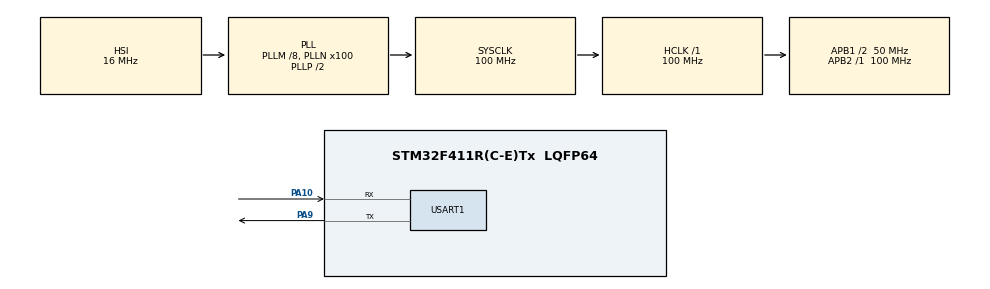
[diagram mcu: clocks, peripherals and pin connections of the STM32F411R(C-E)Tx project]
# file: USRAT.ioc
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Dma.Request0=USART1_RX
Dma.USART1_RX.0.Direction=DMA_PERIPH_TO_MEMORY
Dma.USART1_RX.0.FIFOMode=DMA_FIFOMODE_DISABLE
Dma.USART1_RX.0.Instance=DMA2_Stream2
Dma.USART1_RX.0.MemDataAlignment=DMA_MDATAALIGN_BYTE
Dma.USART1_RX.0.MemInc=DMA_MINC_ENABLE
Dma.USART1_RX.0.Mode=DMA_NORMAL
Dma.USART1_RX.0.PeriphDataAlignment=DMA_PDATAALIGN_BYTE
Dma.USART1_RX.0.PeriphInc=DMA_PINC_DISABLE
Dma.USART1_RX.0.Priority=DMA_PRIORITY_LOW
Mcu.Family=STM32F4
Mcu.Name=STM32F411R(C-E)Tx
Mcu.Package=LQFP64
NVIC.DMA2_Stream2_IRQn=true\:0\:0\:false\:false\:true\:false\:true\:true
NVIC.PriorityGroup=NVIC_PRIORITYGROUP_4
NVIC.USART1_IRQn=true\:0\:0\:false\:false\:true\:true\:true\:true
PA10.Mode=Asynchronous
PA10.Signal=USART1_RX
PA13.Mode=Serial_Wire
PA13.Signal=SYS_JTMS-SWDIO
PA14.Mode=Serial_Wire
PA14.Signal=SYS_JTCK-SWCLK
PA9.Mode=Asynchronous
PA9.Signal=USART1_TX
PC14-OSC32_IN.Mode=LSE-External-Oscillator
PC14-OSC32_IN.Signal=RCC_OSC32_IN
PC15-OSC32_OUT.Mode=LSE-External-Oscillator
PC15-OSC32_OUT.Signal=RCC_OSC32_OUT
PH0\ -\ OSC_IN.Mode=HSE-External-Oscillator
PH0\ -\ OSC_IN.Signal=RCC_OSC_IN
PH1\ -\ OSC_OUT.Mode=HSE-External-Oscillator
PH1\ -\ OSC_OUT.Signal=RCC_OSC_OUT
ProjectManager.HeapSize=0x200
ProjectManager.StackSize=0x400
ProjectManager.TargetToolchain=MDK-ARM V5.32
RCC.48MHZClocksFreq_Value=50000000
RCC.AHBFreq_Value=100000000
RCC.APB1CLKDivider=RCC_HCLK_DIV2
RCC.APB1Freq_Value=50000000
RCC.APB1TimFreq_Value=100000000
RCC.APB2Freq_Value=100000000
RCC.APB2TimFreq_Value=100000000
RCC.CortexFreq_Value=100000000
RCC.HCLKFreq_Value=100000000
RCC.HSE_VALUE=25000000
RCC.HSI_VALUE=16000000
RCC.PLLM=8
RCC.PLLN=100
RCC.SYSCLKFreq_VALUE=100000000
RCC.SYSCLKSource=RCC_SYSCLKSOURCE_PLLCLK
RCC.VCOOutputFreq_Value=200000000
USART1.VirtualMode=VM_ASYNC
board=custom

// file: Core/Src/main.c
/* USER CODE BEGIN Header */
/**
  ******************************************************************************
  * @file           : main.c
  * @brief          : Main program body
  ******************************************************************************
  * @attention
  *
  * Copyright (c) 2026 STMicroelectronics.
  * All rights reserved.
  *
  * This software is licensed under terms that can be found in the LICENSE file
  * in the root directory of this software component.
  * If no LICENSE file comes with this software, it is provided AS-IS.
  *
  ******************************************************************************
  */
/* USER CODE END Header */
#include "main.h"
#include "dma.h"
#include "usart.h"
#include "gpio.h"

/* USER CODE BEGIN PD */
extern uint8_t RXbuf[50];
/* USER CODE END PD */

void SystemClock_Config(void);

int main(void)
{

  /* MCU Configuration--------------------------------------------------------*/

  /* Reset of all peripherals, Initializes the Flash interface and the Systick. */
  HAL_Init();

  /* Configure the system clock */
  SystemClock_Config();

  /* Initialize all configured peripherals */
  MX_GPIO_Init();
  MX_DMA_Init();
  MX_USART1_UART_Init();

  HAL_UART_Receive_DMA(&huart1, RXbuf, 50);
  __HAL_UART_ENABLE_IT(&huart1,UART_IT_IDLE);

  /* Infinite loop */
  while (1)
  {
	printf("uart TX test\r\n");
	HAL_Delay(500);
  }
}

void SystemClock_Config(void)
{
  RCC_OscInitTypeDef RCC_OscInitStruct = {0};
  RCC_ClkInitTypeDef RCC_ClkInitStruct = {0};

  /** Configure the main internal regulator output voltage
  */
  __HAL_RCC_PWR_CLK_ENABLE();
  __HAL_PWR_VOLTAGESCALING_CONFIG(PWR_REGULATOR_VOLTAGE_SCALE1);

  /** Initializes the RCC Oscillators according to the specified parameters
  * in the RCC_OscInitTypeDef structure.
  */
  RCC_OscInitStruct.OscillatorType = RCC_OSCILLATORTYPE_HSI;
  RCC_OscInitStruct.HSIState = RCC_HSI_ON;
  RCC_OscInitStruct.HSICalibrationValue = RCC_HSICALIBRATION_DEFAULT;
  RCC_OscInitStruct.PLL.PLLState = RCC_PLL_ON;
  RCC_OscInitStruct.PLL.PLLSource = RCC_PLLSOURCE_HSI;
  RCC_OscInitStruct.PLL.PLLM = 8;
  RCC_OscInitStruct.PLL.PLLN = 100;
  RCC_OscInitStruct.PLL.PLLP = RCC_PLLP_DIV2;
  RCC_OscInitStruct.PLL.PLLQ = 4;
  if (HAL_RCC_OscConfig(&RCC_OscInitStruct) != HAL_OK)
  {
    Error_Handler();
  }

  /** Initializes the CPU, AHB and APB buses clocks
  */
  RCC_ClkInitStruct.ClockType = RCC_CLOCKTYPE_HCLK|RCC_CLOCKTYPE_SYSCLK
                              |RCC_CLOCKTYPE_PCLK1|RCC_CLOCKTYPE_PCLK2;
  RCC_ClkInitStruct.SYSCLKSource = RCC_SYSCLKSOURCE_PLLCLK;
  RCC_ClkInitStruct.AHBCLKDivider = RCC_SYSCLK_DIV1;
  RCC_ClkInitStruct.APB1CLKDivider = RCC_HCLK_DIV2;
  RCC_ClkInitStruct.APB2CLKDivider = RCC_HCLK_DIV1;

  if (HAL_RCC_ClockConfig(&RCC_ClkInitStruct, FLASH_LATENCY_3) != HAL_OK)
  {
    Error_Handler();
  }
}

void Error_Handler(void)
{
  __disable_irq();
  while (1)
  {
  }
}
